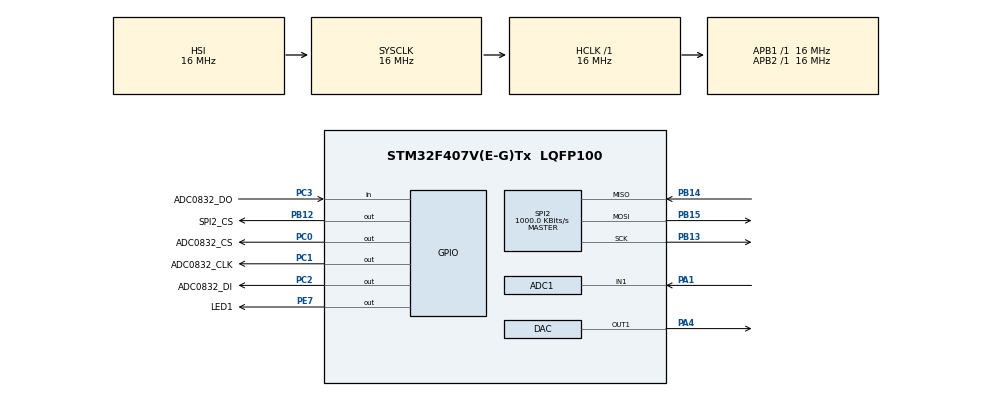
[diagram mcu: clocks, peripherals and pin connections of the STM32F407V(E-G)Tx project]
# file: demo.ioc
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ADC1.Channel-0\#ChannelRegularConversion=ADC_CHANNEL_1
ADC1.NbrOfConversionFlag=1
ADC1.Rank-0\#ChannelRegularConversion=1
ADC1.SamplingTime-0\#ChannelRegularConversion=ADC_SAMPLETIME_144CYCLES
ADC1.master=1
Mcu.Family=STM32F4
Mcu.Name=STM32F407V(E-G)Tx
Mcu.Package=LQFP100
NVIC.PriorityGroup=NVIC_PRIORITYGROUP_4
PA1.Signal=ADCx_IN1
PA4.Signal=COMP_DAC1_group
PB12.GPIO_Label=SPI2_CS
PB12.GPIO_Speed=GPIO_SPEED_FREQ_VERY_HIGH
PB12.PinState=GPIO_PIN_SET
PB12.Signal=GPIO_Output
PB13.Mode=Full_Duplex_Master
PB13.Signal=SPI2_SCK
PB14.Mode=Full_Duplex_Master
PB14.Signal=SPI2_MISO
PB15.Mode=Full_Duplex_Master
PB15.Signal=SPI2_MOSI
PC0.GPIO_Label=ADC0832_CS
PC0.PinState=GPIO_PIN_SET
PC0.Signal=GPIO_Output
PC1.GPIO_Label=ADC0832_CLK
PC1.Signal=GPIO_Output
PC14-OSC32_IN.Mode=LSE-External-Oscillator
PC14-OSC32_IN.Signal=RCC_OSC32_IN
PC15-OSC32_OUT.Mode=LSE-External-Oscillator
PC15-OSC32_OUT.Signal=RCC_OSC32_OUT
PC2.GPIO_Label=ADC0832_DI
PC2.Signal=GPIO_Output
PC3.GPIO_Label=ADC0832_DO
PC3.Signal=GPIO_Input
PE7.GPIO_Label=LED1
PE7.Signal=GPIO_Output
PH0-OSC_IN.Mode=HSE-External-Oscillator
PH0-OSC_IN.Signal=RCC_OSC_IN
PH1-OSC_OUT.Mode=HSE-External-Oscillator
PH1-OSC_OUT.Signal=RCC_OSC_OUT
ProjectManager.HeapSize=0x200
ProjectManager.StackSize=0x400
ProjectManager.TargetToolchain=CMake
RCC.AHBFreq_Value=16000000
RCC.APB1Freq_Value=16000000
RCC.APB2Freq_Value=16000000
RCC.CortexFreq_Value=16000000
RCC.HSE_VALUE=25000000
RCC.HSI_VALUE=16000000
RCC.SYSCLKFreq_VALUE=16000000
RCC.VCOOutputFreq_Value=192000000
SH.ADCx_IN1.0=ADC1_IN1,IN1
SH.COMP_DAC1_group.0=DAC_OUT1,DAC_OUT1
SPI2.BaudRatePrescaler=SPI_BAUDRATEPRESCALER_16
SPI2.CalculateBaudRate=1000.0 KBits/s
SPI2.Direction=SPI_DIRECTION_2LINES
SPI2.Mode=SPI_MODE_MASTER
SPI2.VirtualType=VM_MASTER
board=custom

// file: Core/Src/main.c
/* USER CODE BEGIN Header */
/**
  ******************************************************************************
  * @file           : main.c
  * @brief          : Main program body
  ******************************************************************************
  * @attention
  *
  * Copyright (c) 2026 STMicroelectronics.
  * All rights reserved.
  *
  * This software is licensed under terms that can be found in the LICENSE file
  * in the root directory of this software component.
  * If no LICENSE file comes with this software, it is provided AS-IS.
  *
  ******************************************************************************
  */
/* USER CODE END Header */
#include "main.h"
#include "adc.h"
#include "dac.h"
#include "spi.h"
#include "gpio.h"

/* USER CODE BEGIN Includes */
#include "spilink.h"

/* USER CODE END Includes */

void SystemClock_Config(void);

int main(void)
{

  /* MCU Configuration--------------------------------------------------------*/

  /* Reset of all peripherals, Initializes the Flash interface and the Systick. */
  HAL_Init();

  /* Configure the system clock */
  SystemClock_Config();

  /* Initialize all configured peripherals */
  MX_GPIO_Init();
  MX_SPI2_Init();
  MX_ADC1_Init();
  MX_DAC_Init();
  /* USER CODE BEGIN 2 */
  HAL_DAC_Start(&hdac, DAC_CHANNEL_1);
  SpiLink_Init();

  /* USER CODE END 2 */

  /* Infinite loop */
  /* USER CODE BEGIN WHILE */
  while (1)
  {
    SpiLink_Task();
    /* USER CODE END WHILE */

  }
}

void SystemClock_Config(void)
{
  RCC_OscInitTypeDef RCC_OscInitStruct = {0};
  RCC_ClkInitTypeDef RCC_ClkInitStruct = {0};

  /** Configure the main internal regulator output voltage
  */
  __HAL_RCC_PWR_CLK_ENABLE();
  __HAL_PWR_VOLTAGESCALING_CONFIG(PWR_REGULATOR_VOLTAGE_SCALE1);

  /** Initializes the RCC Oscillators according to the specified parameters
  * in the RCC_OscInitTypeDef structure.
  */
  RCC_OscInitStruct.OscillatorType = RCC_OSCILLATORTYPE_HSI;
  RCC_OscInitStruct.HSIState = RCC_HSI_ON;
  RCC_OscInitStruct.HSICalibrationValue = RCC_HSICALIBRATION_DEFAULT;
  RCC_OscInitStruct.PLL.PLLState = RCC_PLL_NONE;
  if (HAL_RCC_OscConfig(&RCC_OscInitStruct) != HAL_OK)
  {
    Error_Handler();
  }

  /** Initializes the CPU, AHB and APB buses clocks
  */
  RCC_ClkInitStruct.ClockType = RCC_CLOCKTYPE_HCLK|RCC_CLOCKTYPE_SYSCLK
                              |RCC_CLOCKTYPE_PCLK1|RCC_CLOCKTYPE_PCLK2;
  RCC_ClkInitStruct.SYSCLKSource = RCC_SYSCLKSOURCE_HSI;
  RCC_ClkInitStruct.AHBCLKDivider = RCC_SYSCLK_DIV1;
  RCC_ClkInitStruct.APB1CLKDivider = RCC_HCLK_DIV1;
  RCC_ClkInitStruct.APB2CLKDivider = RCC_HCLK_DIV1;

  if (HAL_RCC_ClockConfig(&RCC_ClkInitStruct, FLASH_LATENCY_0) != HAL_OK)
  {
    Error_Handler();
  }
}

void Error_Handler(void)
{
  __disable_irq();
  while (1)
  {
  }
}
